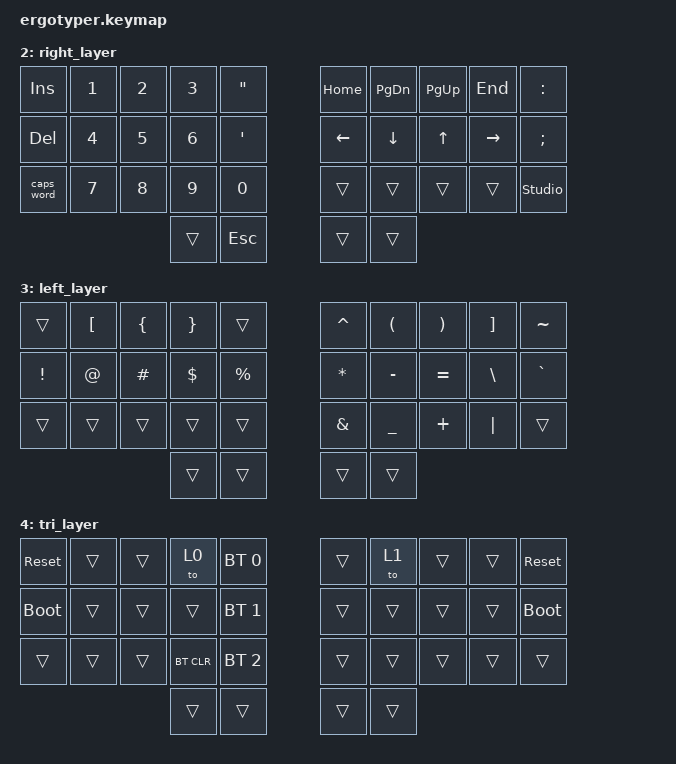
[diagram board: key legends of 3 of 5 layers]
// Copyright (c) 2022 The ZMK Contributors
// SPDX-License-Identifier: MIT

#include <behaviors.dtsi>
#include <dt-bindings/zmk/keys.h>
#include <dt-bindings/zmk/bt.h>

// Home row mods macro
#define HRML(k1,k2,k3,k4) &ht LALT k1  &ht LGUI k2  &ht LSHFT k3  &ht LCTRL k4
#define HRMR(k1,k2,k3,k4) &ht RCTRL k1  &ht RSHFT k2  &ht RGUI k3  &ht RALT k4
#define MEH LC(LS(LALT))

/ {
    behaviors {
        ht: hold_tap {
            compatible = "zmk,behavior-hold-tap";
            #binding-cells = <2>;
            flavor = "tap-preferred";
            tapping-term-ms = <220>;
            quick-tap-ms = <150>;
            require-prior-idle-ms = <100>;
            bindings = <&kp>, <&kp>;
        };
    };

    conditional_layers {
        compatible = "zmk,conditional-layers";
        tri_layer {
            if-layers = <2 3>;
            then-layer = <4>;
        };
    };

    keymap {
        compatible = "zmk,keymap";

        colemak {
            bindings = <
        //╭──────────┬──────────┬──────────┬──────────┬──────────╮   ╭──────────┬──────────┬──────────┬──────────┬──────────╮
        //│  Q       │  W       │  F       │  P       │  B       │   │  J       │  L       │  U       │  Y       │  ;       │
            &kp Q      &kp W      &kp F      &kp P      &kp B          &kp J      &kp L      &kp U      &kp Y      &kp SEMI
        //├──────────┼──────────┼──────────┼──────────┼──────────┤   ├──────────┼──────────┼──────────┼──────────┼──────────┤
        //│  A       │  R       │  S       │  T       │  G       │   │  M       │  N       │  E       │  I       │  O       │
            HRML(A,        R,         S,         T)     &kp G          &kp M      HRMR(N,        E,         I,        O)
        //├──────────┼──────────┼──────────┼──────────┼──────────┤   ├──────────┼──────────┼──────────┼──────────┼──────────┤
        //│  Z       │  X       │  C       │  D       │  V       │   │  K       │  H       │ , <      │ . >      │ / ?      │
            &kp Z      &kp X      &kp C      &kp D      &kp V          &kp K      &kp H      &kp COMMA  &kp DOT    &kp FSLH
        //╰──────────┴──────────┴──────────┴──────────┼──────────┤   ├──────────┼──────────┴──────────┴──────────┴──────────╯
                                            &lt 3 TAB   &kp ENTER     &mt MEH SPACE  &lt 2 BSPC
        //                                 ╰──────────┴──────────╯   ╰──────────┴──────────╯
            >;
        };

        qwerty {
            bindings = <
        //╭──────────┬──────────┬──────────┬──────────┬──────────╮   ╭──────────┬──────────┬──────────┬──────────┬──────────╮
        //│  Q       │  W       │  E       │  R       │  T       │   │  Y       │  U       │  I       │  O       │  P       │
            &kp Q      &kp W      &kp E      &kp R      &kp T          &kp Y      &kp U      &kp I      &kp O      &kp P
        //├──────────┼──────────┼──────────┼──────────┼──────────┤   ├──────────┼──────────┼──────────┼──────────┼──────────┤
        //│  A       │  S       │  D       │  F       │  G       │   │  H       │  J       │  K       │  L       │ ' "      │
            HRML(A,        S,         D,         F)     &kp G          &kp H      HRMR(J,        K,         L,        SQT)
        //├──────────┼──────────┼──────────┼──────────┼──────────┤   ├──────────┼──────────┼──────────┼──────────┼──────────┤
        //│  Z       │  X       │  C       │  V       │  B       │   │  N       │  M       │ , <      │ . >      │ / ?      │
            &kp Z      &kp X      &kp C      &kp V      &kp B          &kp N      &kp M      &kp COMMA  &kp DOT    &kp FSLH
        //╰──────────┴──────────┴──────────┴──────────┼──────────┤   ├──────────┼──────────┴──────────┴──────────┴──────────╯
                                            &lt 3 TAB   &kp ENTER     &mt MEH SPACE  &lt 2 BSPC
        //                                 ╰──────────┴──────────╯   ╰──────────┴──────────╯
            >;
        };
        
        right_layer {
            bindings = <
        //╭──────────┬──────────┬──────────┬──────────┬──────────╮   ╭──────────┬──────────┬──────────┬──────────┬──────────╮
        //│ INSERT   │  1       │  2       │  3       │          │   │ HOME     │ PAGE DN  │ PAGE UP  │ END      │  :       │
            &kp INS    &kp N1     &kp N2     &kp N3     &kp DQT        &kp HOME   &kp PG_DN  &kp PG_UP  &kp END    &kp COLON
        //├──────────┼──────────┼──────────┼──────────┼──────────┤   ├──────────┼──────────┼──────────┼──────────┼──────────┤
        //│ DELETE   │  4       │  5       │  6       │          │   │ LEFT     │ DOWN     │ UP       │ RIGHT    │  ;       │
            &kp DEL    &kp N4     &kp N5     &kp N6     &kp SQT        &kp LEFT   &kp DOWN   &kp UP     &kp RIGHT  &kp SEMI
        //├──────────┼──────────┼──────────┼──────────┼──────────┤   ├──────────┼──────────┼──────────┼──────────┼──────────┤
        //│ CAPS     │  7       │  8       │  9       │  0       │   │          │          │          │          │          │
           &caps_word  &kp N7     &kp N8     &kp N9     &kp N0         &trans     &trans     &trans     &trans     &studio_unlock
        //╰──────────┴──────────┴──────────┴──────────┼──────────┤   ├──────────┼──────────┴──────────┴──────────┴──────────╯
                                             &trans     &kp ESC        &trans     &trans
        //                                 ╰──────────┴──────────╯   ╰──────────┴──────────╯
            >;
        };

        left_layer {
            bindings = <
        //╭──────────┬──────────┬──────────┬──────────┬──────────╮   ╭──────────┬──────────┬──────────┬──────────┬──────────╮
        //│          │  [       │  {       │  }       │          │   │  ^       │  (       │  )       │  ]       │  ~       │
            &trans     &kp LBKT   &kp LBRC   &kp RBRC   &trans         &kp CARET  &kp LPAR   &kp RPAR   &kp RBKT   &kp TILDE
        //├──────────┼──────────┼──────────┼──────────┼──────────┤   ├──────────┼──────────┼──────────┼──────────┼──────────┤
        //│  !       │  @       │  #       │  $       │  %       │   │  *       │  -       │  =       │  \       │  `       │
            &kp EXCL   &kp AT     &kp HASH   &kp DLLR   &kp PRCNT      &kp ASTRK  &kp MINUS  &kp EQUAL  &kp BSLH   &kp GRAVE
        //├──────────┼──────────┼──────────┼──────────┼──────────┤   ├──────────┼──────────┼──────────┼──────────┼──────────┤
        //│          │          │          │          │          │   │  &       │  _       │  +       │  │       │          │
            &trans     &trans     &trans     &trans     &trans         &kp AMPS   &kp UNDER  &kp PLUS   &kp PIPE   &trans
        //╰──────────┴──────────┴──────────┴──────────┼──────────┤   ├──────────┼──────────┴──────────┴──────────┴──────────╯
                                             &trans     &trans         &trans     &trans
        //                                 ╰──────────┴──────────╯   ╰──────────┴──────────╯
            >;
        };

        tri_layer {
            bindings = <
        //╭──────────┬──────────┬──────────┬──────────┬──────────╮   ╭──────────┬──────────┬──────────┬──────────┬──────────╮
        //│ RESET    │          │          │          │PROFILE 0 │   │          │          │          │          │  RESET   │
           &sys_reset  &trans     &trans     &to 0    &bt BT_SEL 0    &trans     &to 1     &trans     &trans    &sys_reset
        //├──────────┼──────────┼──────────┼──────────┼──────────┤   ├──────────┼──────────┼──────────┼──────────┼──────────┤
        //│BOOTLOADER│          │          │          │PROFILE 1 │   │          │          │          │          │BOOTLOADER│
          &bootloader  &trans     &trans     &trans    &bt BT_SEL 1    &trans     &trans     &trans     &trans    &bootloader
        //├──────────┼──────────┼──────────┼──────────┼──────────┤   ├──────────┼──────────┼──────────┼──────────┼──────────┤
        //│          │          │          │ CLEAR BT │PROFILE 2 │   │          │          │          │          │          │
            &trans     &trans     &trans    &bt BT_CLR &bt BT_SEL 2    &trans     &trans     &trans     &trans     &trans
        //╰──────────┴──────────┴──────────┴──────────┼──────────┤   ├──────────┼──────────┴──────────┴──────────┴──────────╯
                                             &trans     &trans         &trans     &trans
        //                                 ╰──────────┴──────────╯   ╰──────────┴──────────╯
            >;
        };
        
        extra1 {
            status = "reserved";
        };

        extra2 {
            status = "reserved";
        };
    };
};
